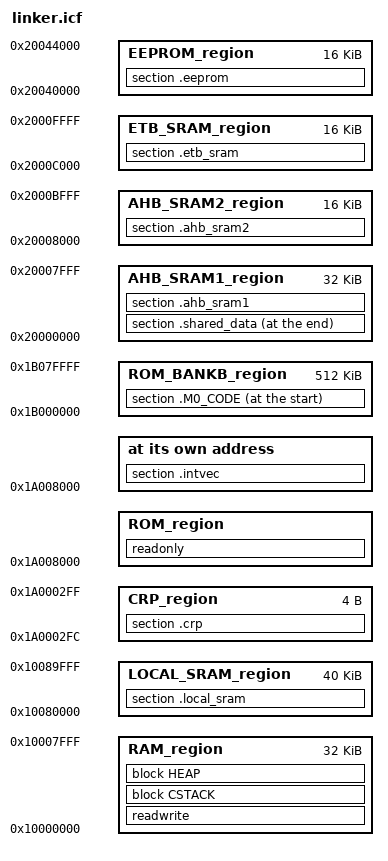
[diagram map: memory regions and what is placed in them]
/*###ICF### Section handled by ICF editor, don't touch! ****/
/*-Editor annotation file-*/
/* IcfEditorFile="$TOOLKIT_DIR$\config\ide\IcfEditor\cortex_v1_0.xml" */
/*-Specials-*/
define symbol __ICFEDIT_intvec_start__ = 0x1A008000;
/*-Memory Regions-*/
define symbol __ICFEDIT_region_ROM_start__ = 0x1A008000;
define symbol __ICFEDIT_region_ROM_end__   = 0x1A07FFFF;
define symbol __ICFEDIT_region_RAM_start__ = 0x10000000;
define symbol __ICFEDIT_region_RAM_end__   = 0x10007FFF;
/*-Sizes-*/
define symbol __ICFEDIT_size_cstack__ = 0x2000;
define symbol __ICFEDIT_size_heap__   = 0x2000;
/**** End of ICF editor section. ###ICF###*/

/********** Flash BankB Region **********/
define symbol ROM_BANKB_start = 0x1B000000;
define symbol ROM_BANKB_end   = 0x1B07FFFF;

/********** Local SRAM Region **********/
define symbol LOCAL_SRAM_start__    = 0x10080000;
define symbol LOCAL_SRAM_end__      = 0x10089FFF;

/********** AHB SRAM Region 1 **********/
define symbol AHB_SRAM1_start__     = 0x20000000;
define symbol AHB_SRAM1_end__       = 0x20007FFF;

/********** AHB SRAM Region 2 **********/
define symbol AHB_SRAM2_start__     = 0x20008000;
define symbol AHB_SRAM2_end__       = 0x2000BFFF;

/********* ETB/AHB SRAM Region *********/
define symbol ETB_SRAM_start__      = 0x2000C000;
define symbol ETB_SRAM_end__        = 0x2000FFFF;

/********* CRP REGION *********/
define symbol __CRP_start__   = 0x1A0002FC;
define symbol __CRP_end__     = 0x1A0002FF;

/********* EEPROM REGION *********/
define symbol __EE_start__   = 0x20040000;
define symbol __EE_end__     = 0x20044000;

define memory mem with size = 4G;
define region ROM_region           = mem:[from __ICFEDIT_region_ROM_start__   to __ICFEDIT_region_ROM_end__] - mem:[from  __CRP_start__ to __CRP_end__];
define region ROM_BANKB_region     = mem:[from ROM_BANKB_start to ROM_BANKB_end];
define region RAM_region           = mem:[from __ICFEDIT_region_RAM_start__   to __ICFEDIT_region_RAM_end__];
define region LOCAL_SRAM_region    = mem:[from LOCAL_SRAM_start__             to LOCAL_SRAM_end__];
define region AHB_SRAM1_region     = mem:[from AHB_SRAM1_start__              to AHB_SRAM1_end__];
define region AHB_SRAM2_region     = mem:[from AHB_SRAM2_start__              to AHB_SRAM2_end__];
define region ETB_SRAM_region      = mem:[from ETB_SRAM_start__               to ETB_SRAM_end__];
define region CRP_region           = mem:[from  __CRP_start__ to __CRP_end__];
define region EEPROM_region        = mem:[from  __EE_start__ to __EE_end__];

define block CSTACK    with alignment = 8, size = __ICFEDIT_size_cstack__   { };
define block HEAP      with alignment = 8, size = __ICFEDIT_size_heap__     { };

initialize by copy { readwrite };
do not initialize  { section .noinit };
do not initialize  { section .eeprom };

place at address mem:__ICFEDIT_intvec_start__ { section .intvec };

place in LOCAL_SRAM_region       { section .local_sram };
place at end of AHB_SRAM1_region { section .shared_data};
place in AHB_SRAM1_region        { section .ahb_sram1 };
place in AHB_SRAM2_region        { section .ahb_sram2 };
place in ETB_SRAM_region         { section .etb_sram };
place in EEPROM_region           { section .eeprom };

place at start of ROM_BANKB_region  { section .M0_CODE };

place in CRP_region              { section .crp };

place in ROM_region              { readonly };
place in RAM_region              { readwrite,
                                   block CSTACK, block HEAP };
